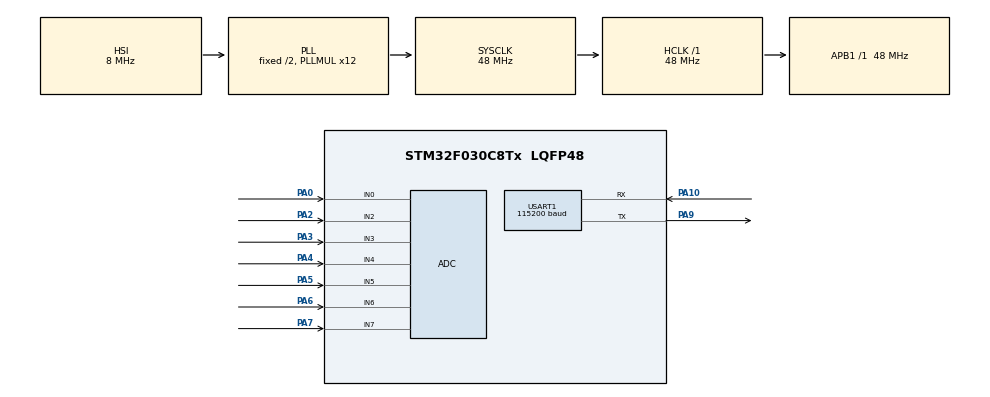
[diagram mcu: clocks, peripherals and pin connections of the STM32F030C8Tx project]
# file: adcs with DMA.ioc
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ADC.ContinuousConvMode=DISABLE
ADC.DMAContinuousRequests=ENABLE
ADC.EOCSelection=ADC_EOC_SEQ_CONV
ADC.SamplingTime=ADC_SAMPLETIME_71CYCLES_5
Dma.ADC.0.Direction=DMA_PERIPH_TO_MEMORY
Dma.ADC.0.Instance=DMA1_Channel1
Dma.ADC.0.MemDataAlignment=DMA_MDATAALIGN_HALFWORD
Dma.ADC.0.MemInc=DMA_MINC_ENABLE
Dma.ADC.0.Mode=DMA_NORMAL
Dma.ADC.0.PeriphDataAlignment=DMA_PDATAALIGN_HALFWORD
Dma.ADC.0.PeriphInc=DMA_PINC_DISABLE
Dma.ADC.0.Priority=DMA_PRIORITY_LOW
Dma.Request0=ADC
Mcu.Family=STM32F0
Mcu.Name=STM32F030C8Tx
Mcu.Package=LQFP48
NVIC.DMA1_Channel1_IRQn=true\:0\:0\:false\:false\:true\:false\:true\:true
PA0.Mode=IN0
PA0.Signal=ADC_IN0
PA10.Mode=Asynchronous
PA10.Signal=USART1_RX
PA13.Mode=Serial_Wire
PA13.Signal=SYS_SWDIO
PA14.Mode=Serial_Wire
PA14.Signal=SYS_SWCLK
PA2.Mode=IN2
PA2.Signal=ADC_IN2
PA3.Mode=IN3
PA3.Signal=ADC_IN3
PA4.Mode=IN4
PA4.Signal=ADC_IN4
PA5.Mode=IN5
PA5.Signal=ADC_IN5
PA6.Mode=IN6
PA6.Signal=ADC_IN6
PA7.Mode=IN7
PA7.Signal=ADC_IN7
PA9.Mode=Asynchronous
PA9.Signal=USART1_TX
PC14-OSC32_IN.Mode=LSE-External-Oscillator
PC14-OSC32_IN.Signal=RCC_OSC32_IN
PC15-OSC32_OUT.Mode=LSE-External-Oscillator
PC15-OSC32_OUT.Signal=RCC_OSC32_OUT
PF0-OSC_IN.Mode=HSE-External-Oscillator
PF0-OSC_IN.Signal=RCC_OSC_IN
PF1-OSC_OUT.Mode=HSE-External-Oscillator
PF1-OSC_OUT.Signal=RCC_OSC_OUT
ProjectManager.HeapSize=0x200
ProjectManager.StackSize=0x400
ProjectManager.TargetToolchain=MDK-ARM V5.32
RCC.AHBFreq_Value=48000000
RCC.APB1Freq_Value=48000000
RCC.APB1TimFreq_Value=48000000
RCC.HCLKFreq_Value=48000000
RCC.PLLMUL=RCC_PLL_MUL12
RCC.SYSCLKFreq_VALUE=48000000
RCC.SYSCLKSource=RCC_SYSCLKSOURCE_PLLCLK
USART1.BaudRate=115200
USART1.VirtualMode-Asynchronous=VM_ASYNC
board=custom

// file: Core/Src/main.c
/* USER CODE BEGIN Header */
/**
  ******************************************************************************
  * @file           : main.c
  * @brief          : Main program body
  ******************************************************************************
  * @attention
  *
  * Copyright (c) 2023 STMicroelectronics.
  * All rights reserved.
  *
  * This software is licensed under terms that can be found in the LICENSE file
  * in the root directory of this software component.
  * If no LICENSE file comes with this software, it is provided AS-IS.
  *
  ******************************************************************************
  */
/* USER CODE END Header */
#include "main.h"
#include "adc.h"
#include "dma.h"
#include "usart.h"
#include "gpio.h"

void SystemClock_Config(void);

/* USER CODE BEGIN 0 */
volatile uint16_t buffer[7];
volatile uint8_t cplt;
/* USER CODE END 0 */

int main(void)
{

  /* MCU Configuration--------------------------------------------------------*/

  /* Reset of all peripherals, Initializes the Flash interface and the Systick. */
  HAL_Init();

  /* Configure the system clock */
  SystemClock_Config();

  /* Initialize all configured peripherals */
  MX_GPIO_Init();
  MX_DMA_Init();
  MX_ADC_Init();
  MX_USART1_UART_Init();
  /* USER CODE BEGIN 2 */
  uint16_t string[100];
  /* USER CODE END 2 */
HAL_ADC_Start_DMA(&hadc,(uint32_t *)buffer,7);
  /* Infinite loop */
  /* USER CODE BEGIN WHILE */
  while (1)
  {
	  HAL_ADC_Start(&hadc);
	  while(cplt==0);
	  cplt=0;

	  sprintf(string,"CH1=%d    CH2=%d    CH3=%d    CH4=%d\r\n",buffer[0],buffer[1],buffer[2],buffer[3]);
	  printf(string);
	  HAL_Delay(200);
    /* USER CODE END WHILE */

  }
}

void SystemClock_Config(void)
{
  RCC_OscInitTypeDef RCC_OscInitStruct = {0};
  RCC_ClkInitTypeDef RCC_ClkInitStruct = {0};
  RCC_PeriphCLKInitTypeDef PeriphClkInit = {0};

  /** Initializes the RCC Oscillators according to the specified parameters
  * in the RCC_OscInitTypeDef structure.
  */
  RCC_OscInitStruct.OscillatorType = RCC_OSCILLATORTYPE_HSI|RCC_OSCILLATORTYPE_HSI14;
  RCC_OscInitStruct.HSIState = RCC_HSI_ON;
  RCC_OscInitStruct.HSI14State = RCC_HSI14_ON;
  RCC_OscInitStruct.HSICalibrationValue = RCC_HSICALIBRATION_DEFAULT;
  RCC_OscInitStruct.HSI14CalibrationValue = 16;
  RCC_OscInitStruct.PLL.PLLState = RCC_PLL_ON;
  RCC_OscInitStruct.PLL.PLLSource = RCC_PLLSOURCE_HSI;
  RCC_OscInitStruct.PLL.PLLMUL = RCC_PLL_MUL12;
  RCC_OscInitStruct.PLL.PREDIV = RCC_PREDIV_DIV1;
  if (HAL_RCC_OscConfig(&RCC_OscInitStruct) != HAL_OK)
  {
    Error_Handler();
  }

  /** Initializes the CPU, AHB and APB buses clocks
  */
  RCC_ClkInitStruct.ClockType = RCC_CLOCKTYPE_HCLK|RCC_CLOCKTYPE_SYSCLK
                              |RCC_CLOCKTYPE_PCLK1;
  RCC_ClkInitStruct.SYSCLKSource = RCC_SYSCLKSOURCE_PLLCLK;
  RCC_ClkInitStruct.AHBCLKDivider = RCC_SYSCLK_DIV1;
  RCC_ClkInitStruct.APB1CLKDivider = RCC_HCLK_DIV1;

  if (HAL_RCC_ClockConfig(&RCC_ClkInitStruct, FLASH_LATENCY_1) != HAL_OK)
  {
    Error_Handler();
  }
  PeriphClkInit.PeriphClockSelection = RCC_PERIPHCLK_USART1;
  PeriphClkInit.Usart1ClockSelection = RCC_USART1CLKSOURCE_PCLK1;
  if (HAL_RCCEx_PeriphCLKConfig(&PeriphClkInit) != HAL_OK)
  {
    Error_Handler();
  }
}

/* USER CODE BEGIN 4 */
void HAL_ADC_ConvHalfCpltCallback(ADC_HandleTypeDef* hadc)
{
	cplt=1;
}
/* USER CODE END 4 */

void Error_Handler(void)
{
  __disable_irq();
  while (1)
  {
  }
}
